AUTOSAR XML (schema 00046)
package /Application1_SWC_ButtonStateReading_package
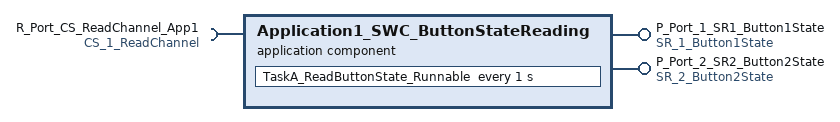
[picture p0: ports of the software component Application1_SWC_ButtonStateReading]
  application sw component type Application1_SWC_ButtonStateReading
    provide port P_Port_1_SR1_Button1State: provided-com-specs=nonqueued-sender-com-spec={data-element=SR_1_Button1State_Element_1, init-value=SR_1_Button1State_Element_1:0}, provided-interface=SR_1_Button1State
    provide port P_Port_2_SR2_Button2State: provided-com-specs=nonqueued-sender-com-spec={data-element=SR_2_Button2State_Element_1, init-value=SR_2_Button2State_Element_1:0}, provided-interface=SR_2_Button2State
    require port R_Port_CS_ReadChannel_App1: client-com-spec=CS_1_ReadChannel_Operation1, required-interface=CS_1_ReadChannel
    behavior Application1_SWC_ButtonStateReading_internal_behavior
      timing event Periodic_Event_1_App1_SWC_event_event: start-on-event=TaskA_ReadButtonState_Runnable, period=1
      runnable TaskA_ReadButtonState_Runnable: symbol=TaskA_ReadButtonState
        sync call TaskA_ReadButtonState_Runnable_R_Port_CS_ReadChannel_App1_CS_1_ReadChannel_Operation1: operation=R_Port_CS_ReadChannel_App1.CS_1_ReadChannel_Operation1
